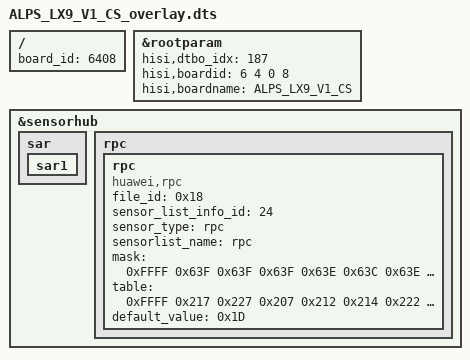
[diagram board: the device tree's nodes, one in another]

/**
 * Copyright (C) 2014 Hisilicon Ltd.
 *
 *  This program is free software; you can redistribute it and/or modify
 *  it under the terms of the GNU General Public License version 2 as
 *  publishhed by the Free Software Foundation.
 */

/dts-v1/;
/plugin/;
/include/ "ALPS_TUGL_V1_CS_overlay.dtsi"

/ {
	board_id=<6408>;
};

&rootparam {
        hisi,dtbo_idx = <187>;
    hisi,boardid = <6 4 0 8>;
    hisi,boardname = "ALPS_LX9_V1_CS";
};

	&sensorhub{
		sar{
			sar1{
				status = "ok";
			};
		};
		rpc{
            		rpc{
			compatible = "huawei,rpc";
			file_id = <0x18>;
			sensor_list_info_id = <24>;
			sensor_type = "rpc";
			sensorlist_name = "rpc";
			mask = <0xFFFF 0x63F 0x63F 0x63F 0x63E 0x63C 0x63E 0x63C
				0x63E 0x63C 0xC20F 0xC20F 0x20F 0x20F 0x20F 0x20F
				0x20F 0x20F 0x20F 0x20F 0xFFFF 0xFFFF 0xFFFF 0xFFFF
				0xFFFF 0xFFFF 0xFFFF 0xFFFF 0xFFFF 0xF 0xFFFF 0xFFFF>;
			table = <0xFFFF 0x217 0x227 0x207 0x212 0x214 0x222 0x224
				 0x202 0x204 0x8002 0x8005 0x2 0x3 0x4 0x5
				 0x6 0x7 0x201 0x1 0xFFFF 0xFFFF 0xFFFF 0xFFFF
				 0xFFFF 0xFFFF 0xFFFF 0xFFFF 0xFFFF 0x0 0xFFFF 0xFFFF>;
			default_value = <0x1D>;
			status = "ok";
            };
        };

};
